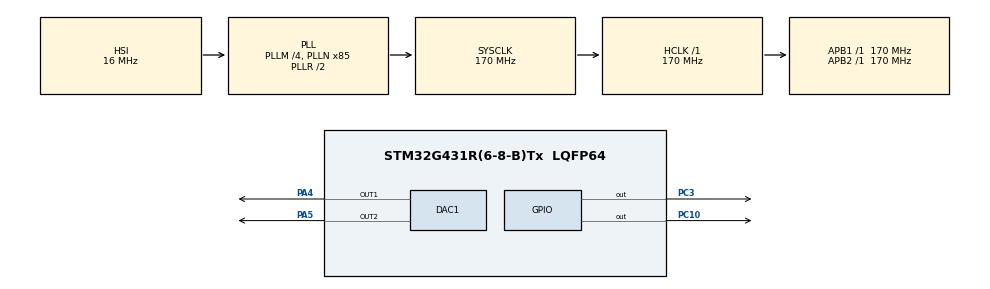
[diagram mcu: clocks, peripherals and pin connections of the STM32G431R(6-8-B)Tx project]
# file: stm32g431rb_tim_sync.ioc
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DAC1.DAC_Channel-DAC_OUT2=DAC_CHANNEL_2
Mcu.Family=STM32G4
Mcu.Name=STM32G431R(6-8-B)Tx
Mcu.Package=LQFP64
NVIC.PriorityGroup=NVIC_PRIORITYGROUP_4
NVIC.TIM1_UP_TIM16_IRQn=true\:0\:0\:false\:false\:true\:true\:true\:true
NVIC.TIM8_UP_IRQn=true\:0\:0\:false\:false\:true\:true\:true\:true
PA4.Signal=COMP_DAC11_group
PA5.Signal=COMP_DAC12_group
PC10.Signal=GPIO_Output
PC3.Signal=GPIO_Output
ProjectManager.HeapSize=0x200
ProjectManager.StackSize=0x400
ProjectManager.TargetToolchain=STM32CubeIDE
RCC.ADC12Freq_Value=170000000
RCC.AHBFreq_Value=170000000
RCC.APB1Freq_Value=170000000
RCC.APB1TimFreq_Value=170000000
RCC.APB2Freq_Value=170000000
RCC.APB2TimFreq_Value=170000000
RCC.CortexFreq_Value=170000000
RCC.EXTERNAL_CLOCK_VALUE=12288000
RCC.HCLKFreq_Value=170000000
RCC.HSE_VALUE=8000000
RCC.HSI48_VALUE=48000000
RCC.HSI_VALUE=16000000
RCC.LSE_VALUE=32768
RCC.PLLM=RCC_PLLM_DIV4
RCC.PLLN=85
RCC.SYSCLKFreq_VALUE=170000000
RCC.SYSCLKSource=RCC_SYSCLKSOURCE_PLLCLK
RCC.USBFreq_Value=170000000
RCC.VCOOutputFreq_Value=340000000
SH.COMP_DAC11_group.0=DAC1_OUT1,DAC_OUT1
SH.COMP_DAC12_group.0=DAC1_OUT2,DAC_OUT2
TIM1.CounterMode=TIM_COUNTERMODE_CENTERALIGNED1
TIM1.PeriodNoDither=(1000-1)
TIM1.Prescaler=(17000-1)
TIM1.TIM_MasterOutputTrigger=TIM_TRGO_ENABLE
TIM8.CounterMode=TIM_COUNTERMODE_CENTERALIGNED1
TIM8.PeriodNoDither=(1000-1)
TIM8.Prescaler=(17000-1)
VP_SYS_VS_DBSignals.Mode=DisableDeadBatterySignals
VP_TIM1_VS_ClockSourceINT.Mode=Internal
VP_TIM8_VS_ClockSourceITR.Mode=TriggerSource_ITR0
VP_TIM8_VS_ControllerModeGated.Mode=Gated Mode
board=custom

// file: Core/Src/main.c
/* USER CODE BEGIN Header */
/**
  ******************************************************************************
  * @file           : main.c
  * @brief          : Main program body
  ******************************************************************************
  * @attention
  *
  * Copyright (c) 2026 STMicroelectronics.
  * All rights reserved.
  *
  * This software is licensed under terms that can be found in the LICENSE file
  * in the root directory of this software component.
  * If no LICENSE file comes with this software, it is provided AS-IS.
  *
  ******************************************************************************
  */
/* USER CODE END Header */
#include "main.h"

DAC_HandleTypeDef hdac1;

void SystemClock_Config(void);
static void MX_GPIO_Init(void);
static void MX_TIM1_Init(void);
static void MX_TIM8_Init(void);
static void MX_DAC1_Init(void);

int main(void)
{

  /* MCU Configuration--------------------------------------------------------*/

  /* Reset of all peripherals, Initializes the Flash interface and the Systick. */
  HAL_Init();

  /* Configure the system clock */
  SystemClock_Config();

  /* Initialize all configured peripherals */
  MX_GPIO_Init();
  MX_TIM1_Init();
  MX_TIM8_Init();
  MX_DAC1_Init();
  /* USER CODE BEGIN 2 */
  HAL_DAC_Start(&hdac1, DAC_CHANNEL_1);
  HAL_DAC_Start(&hdac1, DAC_CHANNEL_2);

  __HAL_DBGMCU_FREEZE_TIM1();
  __HAL_DBGMCU_FREEZE_TIM8();

  LL_TIM_EnableIT_UPDATE(TIM1);
  LL_TIM_EnableIT_UPDATE(TIM8);

  LL_TIM_SetCounter(TIM8, LL_TIM_GetAutoReload(TIM8));

  LL_TIM_EnableCounter(TIM8);
  HAL_Delay(100);
  LL_TIM_EnableCounter(TIM1);
  /* USER CODE END 2 */

  /* Infinite loop */
  /* USER CODE BEGIN WHILE */
  while (1)
  {
    HAL_DAC_SetValue(&hdac1, DAC_CHANNEL_1, DAC_ALIGN_12B_R, LL_TIM_GetCounter(TIM1));
    HAL_DAC_SetValue(&hdac1, DAC_CHANNEL_2, DAC_ALIGN_12B_R, LL_TIM_GetCounter(TIM8));
    /* USER CODE END WHILE */

  }
}

void SystemClock_Config(void)
{
  RCC_OscInitTypeDef RCC_OscInitStruct = {0};
  RCC_ClkInitTypeDef RCC_ClkInitStruct = {0};

  /** Configure the main internal regulator output voltage
  */
  HAL_PWREx_ControlVoltageScaling(PWR_REGULATOR_VOLTAGE_SCALE1_BOOST);

  /** Initializes the RCC Oscillators according to the specified parameters
  * in the RCC_OscInitTypeDef structure.
  */
  RCC_OscInitStruct.OscillatorType = RCC_OSCILLATORTYPE_HSI;
  RCC_OscInitStruct.HSIState = RCC_HSI_ON;
  RCC_OscInitStruct.HSICalibrationValue = RCC_HSICALIBRATION_DEFAULT;
  RCC_OscInitStruct.PLL.PLLState = RCC_PLL_ON;
  RCC_OscInitStruct.PLL.PLLSource = RCC_PLLSOURCE_HSI;
  RCC_OscInitStruct.PLL.PLLM = RCC_PLLM_DIV4;
  RCC_OscInitStruct.PLL.PLLN = 85;
  RCC_OscInitStruct.PLL.PLLP = RCC_PLLP_DIV2;
  RCC_OscInitStruct.PLL.PLLQ = RCC_PLLQ_DIV2;
  RCC_OscInitStruct.PLL.PLLR = RCC_PLLR_DIV2;
  if (HAL_RCC_OscConfig(&RCC_OscInitStruct) != HAL_OK)
  {
    Error_Handler();
  }

  /** Initializes the CPU, AHB and APB buses clocks
  */
  RCC_ClkInitStruct.ClockType = RCC_CLOCKTYPE_HCLK|RCC_CLOCKTYPE_SYSCLK
                              |RCC_CLOCKTYPE_PCLK1|RCC_CLOCKTYPE_PCLK2;
  RCC_ClkInitStruct.SYSCLKSource = RCC_SYSCLKSOURCE_PLLCLK;
  RCC_ClkInitStruct.AHBCLKDivider = RCC_SYSCLK_DIV1;
  RCC_ClkInitStruct.APB1CLKDivider = RCC_HCLK_DIV1;
  RCC_ClkInitStruct.APB2CLKDivider = RCC_HCLK_DIV1;

  if (HAL_RCC_ClockConfig(&RCC_ClkInitStruct, FLASH_LATENCY_4) != HAL_OK)
  {
    Error_Handler();
  }
}

static void MX_DAC1_Init(void)
{

  DAC_ChannelConfTypeDef sConfig = {0};

  /** DAC Initialization
  */
  hdac1.Instance = DAC1;
  if (HAL_DAC_Init(&hdac1) != HAL_OK)
  {
    Error_Handler();
  }

  /** DAC channel OUT1 config
  */
  sConfig.DAC_HighFrequency = DAC_HIGH_FREQUENCY_INTERFACE_MODE_AUTOMATIC;
  sConfig.DAC_DMADoubleDataMode = DISABLE;
  sConfig.DAC_SignedFormat = DISABLE;
  sConfig.DAC_SampleAndHold = DAC_SAMPLEANDHOLD_DISABLE;
  sConfig.DAC_Trigger = DAC_TRIGGER_NONE;
  sConfig.DAC_Trigger2 = DAC_TRIGGER_NONE;
  sConfig.DAC_OutputBuffer = DAC_OUTPUTBUFFER_ENABLE;
  sConfig.DAC_ConnectOnChipPeripheral = DAC_CHIPCONNECT_EXTERNAL;
  sConfig.DAC_UserTrimming = DAC_TRIMMING_FACTORY;
  if (HAL_DAC_ConfigChannel(&hdac1, &sConfig, DAC_CHANNEL_1) != HAL_OK)
  {
    Error_Handler();
  }

  /** DAC channel OUT2 config
  */
  if (HAL_DAC_ConfigChannel(&hdac1, &sConfig, DAC_CHANNEL_2) != HAL_OK)
  {
    Error_Handler();
  }

}

static void MX_TIM1_Init(void)
{

  LL_TIM_InitTypeDef TIM_InitStruct = {0};

  /* Peripheral clock enable */
  LL_APB2_GRP1_EnableClock(LL_APB2_GRP1_PERIPH_TIM1);

  /* TIM1 interrupt Init */
  NVIC_SetPriority(TIM1_UP_TIM16_IRQn, NVIC_EncodePriority(NVIC_GetPriorityGrouping(),0, 0));
  NVIC_EnableIRQ(TIM1_UP_TIM16_IRQn);

  TIM_InitStruct.Prescaler = 16999;
  TIM_InitStruct.CounterMode = LL_TIM_COUNTERMODE_CENTER_DOWN;
  TIM_InitStruct.Autoreload = (1000-1);
  TIM_InitStruct.ClockDivision = LL_TIM_CLOCKDIVISION_DIV1;
  TIM_InitStruct.RepetitionCounter = 0;
  LL_TIM_Init(TIM1, &TIM_InitStruct);
  LL_TIM_DisableARRPreload(TIM1);
  LL_TIM_SetClockSource(TIM1, LL_TIM_CLOCKSOURCE_INTERNAL);
  LL_TIM_SetTriggerOutput(TIM1, LL_TIM_TRGO_ENABLE);
  LL_TIM_SetTriggerOutput2(TIM1, LL_TIM_TRGO2_RESET);
  LL_TIM_DisableMasterSlaveMode(TIM1);

}

static void MX_TIM8_Init(void)
{

  LL_TIM_InitTypeDef TIM_InitStruct = {0};

  /* Peripheral clock enable */
  LL_APB2_GRP1_EnableClock(LL_APB2_GRP1_PERIPH_TIM8);

  /* TIM8 interrupt Init */
  NVIC_SetPriority(TIM8_UP_IRQn, NVIC_EncodePriority(NVIC_GetPriorityGrouping(),0, 0));
  NVIC_EnableIRQ(TIM8_UP_IRQn);

  TIM_InitStruct.Prescaler = (17000-1);
  TIM_InitStruct.CounterMode = LL_TIM_COUNTERMODE_CENTER_DOWN;
  TIM_InitStruct.Autoreload = (1000-1);
  TIM_InitStruct.ClockDivision = LL_TIM_CLOCKDIVISION_DIV1;
  TIM_InitStruct.RepetitionCounter = 0;
  LL_TIM_Init(TIM8, &TIM_InitStruct);
  LL_TIM_DisableARRPreload(TIM8);
  LL_TIM_SetTriggerInput(TIM8, LL_TIM_TS_ITR0);
  LL_TIM_SetSlaveMode(TIM8, LL_TIM_SLAVEMODE_GATED);
  LL_TIM_DisableIT_TRIG(TIM8);
  LL_TIM_DisableDMAReq_TRIG(TIM8);
  LL_TIM_SetTriggerOutput(TIM8, LL_TIM_TRGO_RESET);
  LL_TIM_SetTriggerOutput2(TIM8, LL_TIM_TRGO2_RESET);
  LL_TIM_DisableMasterSlaveMode(TIM8);

}

static void MX_GPIO_Init(void)
{
  LL_GPIO_InitTypeDef GPIO_InitStruct = {0};

  /* GPIO Ports Clock Enable */
  LL_AHB2_GRP1_EnableClock(LL_AHB2_GRP1_PERIPH_GPIOC);
  LL_AHB2_GRP1_EnableClock(LL_AHB2_GRP1_PERIPH_GPIOA);

  /**/
  LL_GPIO_ResetOutputPin(GPIOC, LL_GPIO_PIN_3);

  /**/
  LL_GPIO_ResetOutputPin(GPIOC, LL_GPIO_PIN_10);

  /**/
  GPIO_InitStruct.Pin = LL_GPIO_PIN_3;
  GPIO_InitStruct.Mode = LL_GPIO_MODE_OUTPUT;
  GPIO_InitStruct.Speed = LL_GPIO_SPEED_FREQ_LOW;
  GPIO_InitStruct.OutputType = LL_GPIO_OUTPUT_PUSHPULL;
  GPIO_InitStruct.Pull = LL_GPIO_PULL_NO;
  LL_GPIO_Init(GPIOC, &GPIO_InitStruct);

  /**/
  GPIO_InitStruct.Pin = LL_GPIO_PIN_10;
  GPIO_InitStruct.Mode = LL_GPIO_MODE_OUTPUT;
  GPIO_InitStruct.Speed = LL_GPIO_SPEED_FREQ_LOW;
  GPIO_InitStruct.OutputType = LL_GPIO_OUTPUT_PUSHPULL;
  GPIO_InitStruct.Pull = LL_GPIO_PULL_NO;
  LL_GPIO_Init(GPIOC, &GPIO_InitStruct);

}

void Error_Handler(void)
{
  __disable_irq();
  while (1)
  {
  }
}
